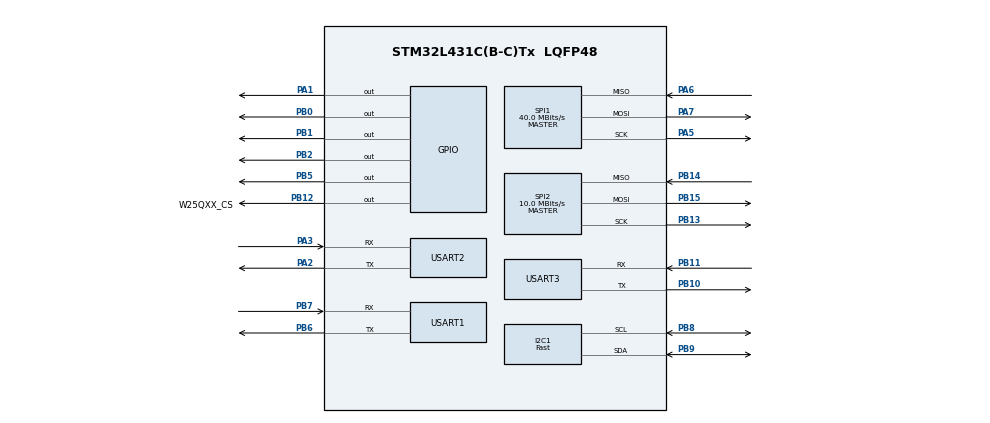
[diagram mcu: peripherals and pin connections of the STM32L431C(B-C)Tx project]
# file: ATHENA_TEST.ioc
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Dma.I2C1_RX.0.Direction=DMA_PERIPH_TO_MEMORY
Dma.I2C1_RX.0.Instance=DMA1_Channel7
Dma.I2C1_RX.0.MemDataAlignment=DMA_MDATAALIGN_BYTE
Dma.I2C1_RX.0.MemInc=DMA_MINC_ENABLE
Dma.I2C1_RX.0.Mode=DMA_NORMAL
Dma.I2C1_RX.0.PeriphDataAlignment=DMA_PDATAALIGN_BYTE
Dma.I2C1_RX.0.PeriphInc=DMA_PINC_DISABLE
Dma.I2C1_RX.0.Priority=DMA_PRIORITY_MEDIUM
Dma.I2C1_TX.1.Direction=DMA_MEMORY_TO_PERIPH
Dma.I2C1_TX.1.Instance=DMA1_Channel6
Dma.I2C1_TX.1.MemDataAlignment=DMA_MDATAALIGN_BYTE
Dma.I2C1_TX.1.MemInc=DMA_MINC_ENABLE
Dma.I2C1_TX.1.Mode=DMA_NORMAL
Dma.I2C1_TX.1.PeriphDataAlignment=DMA_PDATAALIGN_BYTE
Dma.I2C1_TX.1.PeriphInc=DMA_PINC_DISABLE
Dma.I2C1_TX.1.Priority=DMA_PRIORITY_MEDIUM
Dma.Request0=I2C1_RX
Dma.Request1=I2C1_TX
Dma.Request2=USART1_RX
Dma.Request3=USART1_TX
Dma.Request4=SPI2_RX
Dma.Request5=SPI2_TX
Dma.SPI2_RX.4.Direction=DMA_PERIPH_TO_MEMORY
Dma.SPI2_RX.4.Instance=DMA1_Channel4
Dma.SPI2_RX.4.MemDataAlignment=DMA_MDATAALIGN_BYTE
Dma.SPI2_RX.4.MemInc=DMA_MINC_ENABLE
Dma.SPI2_RX.4.Mode=DMA_NORMAL
Dma.SPI2_RX.4.PeriphDataAlignment=DMA_PDATAALIGN_BYTE
Dma.SPI2_RX.4.PeriphInc=DMA_PINC_DISABLE
Dma.SPI2_RX.4.Priority=DMA_PRIORITY_LOW
Dma.SPI2_TX.5.Direction=DMA_MEMORY_TO_PERIPH
Dma.SPI2_TX.5.Instance=DMA1_Channel5
Dma.SPI2_TX.5.MemDataAlignment=DMA_MDATAALIGN_BYTE
Dma.SPI2_TX.5.MemInc=DMA_MINC_ENABLE
Dma.SPI2_TX.5.Mode=DMA_NORMAL
Dma.SPI2_TX.5.PeriphDataAlignment=DMA_PDATAALIGN_BYTE
Dma.SPI2_TX.5.PeriphInc=DMA_PINC_DISABLE
Dma.SPI2_TX.5.Priority=DMA_PRIORITY_LOW
Dma.USART1_RX.2.Direction=DMA_PERIPH_TO_MEMORY
Dma.USART1_RX.2.Instance=DMA2_Channel7
Dma.USART1_RX.2.MemDataAlignment=DMA_MDATAALIGN_BYTE
Dma.USART1_RX.2.MemInc=DMA_MINC_ENABLE
Dma.USART1_RX.2.Mode=DMA_NORMAL
Dma.USART1_RX.2.PeriphDataAlignment=DMA_PDATAALIGN_BYTE
Dma.USART1_RX.2.PeriphInc=DMA_PINC_DISABLE
Dma.USART1_RX.2.Priority=DMA_PRIORITY_LOW
Dma.USART1_TX.3.Direction=DMA_MEMORY_TO_PERIPH
Dma.USART1_TX.3.Instance=DMA2_Channel6
Dma.USART1_TX.3.MemDataAlignment=DMA_MDATAALIGN_BYTE
Dma.USART1_TX.3.MemInc=DMA_MINC_ENABLE
Dma.USART1_TX.3.Mode=DMA_NORMAL
Dma.USART1_TX.3.PeriphDataAlignment=DMA_PDATAALIGN_BYTE
Dma.USART1_TX.3.PeriphInc=DMA_PINC_DISABLE
Dma.USART1_TX.3.Priority=DMA_PRIORITY_LOW
FREERTOS.Tasks01=defaultTask,24,128,StartDefaultTask,Default,NULL,Dynamic,NULL,NULL;SPI_test_task,8,128,StartTask02,Default,NULL,Dynamic,NULL,NULL
I2C1.GeneralCallMode=I2C_GENERALCALL_ENABLE
I2C1.I2C_Speed_Mode=I2C_Fast
I2C1.Timing=0x00702991
Mcu.Family=STM32L4
Mcu.Name=STM32L431C(B-C)Tx
Mcu.Package=LQFP48
NVIC.DMA1_Channel4_IRQn=true\:5\:0\:false\:false\:true\:true\:false\:true\:true
NVIC.DMA1_Channel5_IRQn=true\:5\:0\:false\:false\:true\:true\:false\:true\:true
NVIC.DMA1_Channel6_IRQn=true\:5\:0\:false\:false\:true\:true\:false\:true\:true
NVIC.DMA1_Channel7_IRQn=true\:5\:0\:false\:false\:true\:true\:false\:true\:true
NVIC.DMA2_Channel6_IRQn=true\:5\:0\:false\:false\:true\:false\:false\:true\:true
NVIC.DMA2_Channel7_IRQn=true\:5\:0\:false\:false\:true\:false\:false\:true\:true
NVIC.I2C1_ER_IRQn=true\:5\:0\:false\:false\:true\:true\:true\:true\:true
NVIC.I2C1_EV_IRQn=true\:5\:0\:false\:false\:true\:true\:true\:true\:true
NVIC.PriorityGroup=NVIC_PRIORITYGROUP_4
NVIC.SPI2_IRQn=true\:5\:0\:false\:false\:true\:true\:true\:true\:true
NVIC.USART1_IRQn=true\:5\:0\:false\:false\:true\:true\:true\:true\:true
NVIC.USART2_IRQn=true\:5\:0\:false\:false\:true\:true\:true\:true\:true
NVIC.USART3_IRQn=true\:5\:0\:false\:false\:true\:true\:true\:true\:true
PA1.Signal=GPIO_Output
PA13\ (JTMS-SWDIO).Mode=Trace_Asynchronous_SW
PA13\ (JTMS-SWDIO).Signal=SYS_JTMS-SWDIO
PA14\ (JTCK-SWCLK).Mode=Trace_Asynchronous_SW
PA14\ (JTCK-SWCLK).Signal=SYS_JTCK-SWCLK
PA2.Mode=Asynchronous
PA2.Signal=USART2_TX
PA3.Mode=Asynchronous
PA3.Signal=USART2_RX
PA5.Mode=Full_Duplex_Master
PA5.Signal=SPI1_SCK
PA6.Mode=Full_Duplex_Master
PA6.Signal=SPI1_MISO
PA7.GPIO_PuPd=GPIO_NOPULL
PA7.Mode=Full_Duplex_Master
PA7.Signal=SPI1_MOSI
PB0.Signal=GPIO_Output
PB1.Signal=GPIO_Output
PB10.Mode=Asynchronous
PB10.Signal=USART3_TX
PB11.Mode=Asynchronous
PB11.Signal=USART3_RX
PB12.GPIO_Label=W25QXX_CS
PB12.GPIO_PuPd=GPIO_PULLUP
PB12.GPIO_Speed=GPIO_SPEED_FREQ_HIGH
PB12.PinState=GPIO_PIN_SET
PB12.Signal=GPIO_Output
PB13.Mode=Full_Duplex_Master
PB13.Signal=SPI2_SCK
PB14.Mode=Full_Duplex_Master
PB14.Signal=SPI2_MISO
PB15.Mode=Full_Duplex_Master
PB15.Signal=SPI2_MOSI
PB2.Signal=GPIO_Output
PB3\ (JTDO-TRACESWO).Mode=Trace_Asynchronous_SW
PB3\ (JTDO-TRACESWO).Signal=SYS_JTDO-SWO
PB5.Signal=GPIO_Output
PB6.Mode=Asynchronous
PB6.Signal=USART1_TX
PB7.Mode=Asynchronous
PB7.Signal=USART1_RX
PB8.Mode=I2C
PB8.Signal=I2C1_SCL
PB9.Mode=I2C
PB9.Signal=I2C1_SDA
PH0-OSC_IN\ (PH0).Mode=HSE-External-Oscillator
PH0-OSC_IN\ (PH0).Signal=RCC_OSC_IN
PH1-OSC_OUT\ (PH1).Mode=HSE-External-Oscillator
PH1-OSC_OUT\ (PH1).Signal=RCC_OSC_OUT
ProjectManager.HeapSize=0x200
ProjectManager.StackSize=0x400
ProjectManager.TargetToolchain=STM32CubeIDE
RCC.ADCFreq_Value=32000000
RCC.AHBFreq_Value=80000000
RCC.APB1Freq_Value=80000000
RCC.APB1TimFreq_Value=80000000
RCC.APB2Freq_Value=80000000
RCC.APB2TimFreq_Value=80000000
RCC.CortexFreq_Value=80000000
RCC.HCLKFreq_Value=80000000
RCC.HSE_VALUE=8000000
RCC.HSI48_VALUE=48000000
RCC.HSI_VALUE=16000000
RCC.LSE_VALUE=32768
RCC.MSI_VALUE=4000000
RCC.PLLN=20
RCC.PLLSourceVirtual=RCC_PLLSOURCE_HSE
RCC.SYSCLKFreq_VALUE=80000000
RCC.SYSCLKSource=RCC_SYSCLKSOURCE_PLLCLK
RCC.VCOOutputFreq_Value=160000000
RCC.VDD_VALUE=3
SPI1.CalculateBaudRate=40.0 MBits/s
SPI1.Direction=SPI_DIRECTION_2LINES
SPI1.Mode=SPI_MODE_MASTER
SPI1.VirtualType=VM_MASTER
SPI2.BaudRatePrescaler=SPI_BAUDRATEPRESCALER_8
SPI2.CLKPhase=SPI_PHASE_1EDGE
SPI2.CLKPolarity=SPI_POLARITY_LOW
SPI2.CalculateBaudRate=10.0 MBits/s
SPI2.DataSize=SPI_DATASIZE_8BIT
SPI2.Direction=SPI_DIRECTION_2LINES
SPI2.Mode=SPI_MODE_MASTER
SPI2.VirtualType=VM_MASTER
USART1.VirtualMode-Asynchronous=VM_ASYNC
USART2.VirtualMode-Asynchronous=VM_ASYNC
USART3.VirtualMode-Asynchronous=VM_ASYNC
VP_FREERTOS_VS_CMSIS_V2.Mode=CMSIS_V2
board=custom

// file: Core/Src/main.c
/* USER CODE BEGIN Header */
/**
 ******************************************************************************
 * @file           : main.c
 * @brief          : Main program body
 ******************************************************************************
 * @attention
 *
 * Copyright (c) 2024 STMicroelectronics.
 * All rights reserved.
 *
 * This software is licensed under terms that can be found in the LICENSE file
 * in the root directory of this software component.
 * If no LICENSE file comes with this software, it is provided AS-IS.
 *
 ******************************************************************************
 */
/* USER CODE END Header */
#include "main.h"
#include "cmsis_os.h"
#include "dma.h"
#include "i2c.h"
#include "spi.h"
#include "usart.h"
#include "gpio.h"

void SystemClock_Config(void);
void MX_FREERTOS_Init(void);

int main(void) {

	/* MCU Configuration--------------------------------------------------------*/

	/* Reset of all peripherals, Initializes the Flash interface and the Systick. */
	LL_APB2_GRP1_EnableClock(LL_APB2_GRP1_PERIPH_SYSCFG);
	LL_APB1_GRP1_EnableClock(LL_APB1_GRP1_PERIPH_PWR);

	/* System interrupt init*/
	NVIC_SetPriorityGrouping(NVIC_PRIORITYGROUP_4);

	/* PendSV_IRQn interrupt configuration */
	NVIC_SetPriority(PendSV_IRQn,
			NVIC_EncodePriority(NVIC_GetPriorityGrouping(), 15, 0));
	/* SysTick_IRQn interrupt configuration */
	NVIC_SetPriority(SysTick_IRQn,
			NVIC_EncodePriority(NVIC_GetPriorityGrouping(), 15, 0));

	/* Configure the system clock */
	SystemClock_Config();

	/* Initialize all configured peripherals */
	MX_GPIO_Init();
	MX_DMA_Init();
	MX_I2C1_Init();
	MX_USART1_UART_Init();
	MX_SPI1_Init();
	MX_SPI2_Init();
	MX_USART2_UART_Init();
	MX_USART3_UART_Init();

	/* Init scheduler */
	osKernelInitialize();

	/* Call init function for freertos objects (in cmsis_os2.c) */
	MX_FREERTOS_Init();

	/* Start scheduler */
	osKernelStart();

	/* We should never get here as control is now taken by the scheduler */

	/* Infinite loop */
	while (1) {

	}
}

void SystemClock_Config(void) {
	LL_FLASH_SetLatency(LL_FLASH_LATENCY_4);
	while (LL_FLASH_GetLatency() != LL_FLASH_LATENCY_4) {
	}
	LL_PWR_SetRegulVoltageScaling(LL_PWR_REGU_VOLTAGE_SCALE1);
	while (LL_PWR_IsActiveFlag_VOS() != 0) {
	}
	LL_RCC_HSE_Enable();

	/* Wait till HSE is ready */
	while (LL_RCC_HSE_IsReady() != 1) {

	}
	LL_RCC_PLL_ConfigDomain_SYS(LL_RCC_PLLSOURCE_HSE, LL_RCC_PLLM_DIV_1, 20,
			LL_RCC_PLLR_DIV_2);
	LL_RCC_PLL_EnableDomain_SYS();
	LL_RCC_PLL_Enable();

	/* Wait till PLL is ready */
	while (LL_RCC_PLL_IsReady() != 1) {

	}
	LL_RCC_SetSysClkSource(LL_RCC_SYS_CLKSOURCE_PLL);

	/* Wait till System clock is ready */
	while (LL_RCC_GetSysClkSource() != LL_RCC_SYS_CLKSOURCE_STATUS_PLL) {

	}
	LL_RCC_SetAHBPrescaler(LL_RCC_SYSCLK_DIV_1);
	LL_RCC_SetAPB1Prescaler(LL_RCC_APB1_DIV_1);
	LL_RCC_SetAPB2Prescaler(LL_RCC_APB2_DIV_1);

	LL_Init1msTick(80000000);

	LL_SetSystemCoreClock(80000000);
}

void Error_Handler(void) {
	__disable_irq();
	while (1) {
	}
}

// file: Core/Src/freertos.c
/* USER CODE BEGIN Header */
/**
  ******************************************************************************
  * File Name          : freertos.c
  * Description        : Code for freertos applications
  ******************************************************************************
  * @attention
  *
  * Copyright (c) 2024 STMicroelectronics.
  * All rights reserved.
  *
  * This software is licensed under terms that can be found in the LICENSE file
  * in the root directory of this software component.
  * If no LICENSE file comes with this software, it is provided AS-IS.
  *
  ******************************************************************************
  */
/* USER CODE END Header */

#include "FreeRTOS.h"
#include "task.h"
#include "main.h"
#include "cmsis_os.h"

/* USER CODE BEGIN Includes */
#include "i2c_drv.h"
#include "spi_drv.h"
#include "tca6408a.h"
#include "vl53l5cx_api.h"
#include "test_tof.h"

#define RX_BUFFER_SIZE 5
static VL53L5CX_Configuration vl53l5dev_f;
static VL53L5CX_ResultsData vl53l5_res_f;
/* USER CODE END Includes */

/* Definitions for defaultTask */
osThreadId_t defaultTaskHandle;
const osThreadAttr_t defaultTask_attributes = {
  .name = "defaultTask",
  .stack_size = 128 * 4,
  .priority = (osPriority_t) osPriorityNormal,
};
/* Definitions for SPI_test_task */
osThreadId_t SPI_test_taskHandle;
const osThreadAttr_t SPI_test_task_attributes = {
  .name = "SPI_test_task",
  .stack_size = 128 * 4,
  .priority = (osPriority_t) osPriorityLow,
};

void StartDefaultTask(void *argument);
void StartTask02(void *argument);

void MX_FREERTOS_Init(void); /* (MISRA C 2004 rule 8.1) */

void MX_FREERTOS_Init(void) {

  /* Create the thread(s) */
  /* creation of defaultTask */
  defaultTaskHandle = osThreadNew(StartDefaultTask, NULL, &defaultTask_attributes);

  /* creation of SPI_test_task */
  //SPI_test_taskHandle = osThreadNew(StartTask02, NULL, &SPI_test_task_attributes);

}

void StartDefaultTask(void *argument)
{
  /* USER CODE BEGIN StartDefaultTask */
//  /* Infinite loop */

    I2C_expander_initialize();
    initialize_sensors_I2C(&vl53l5dev_f,1);
    vl53l5cx_start_ranging(&vl53l5dev_f);
    while(1){
    	LL_GPIO_TogglePin(GPIOA, LL_GPIO_PIN_1);
    	get_sensor_data(&vl53l5dev_f, &vl53l5_res_f);
    	osDelay(5);
    }

  /* USER CODE END StartDefaultTask */
}

void StartTask02(void *argument)
{
  for(;;)
  {
  }
}
